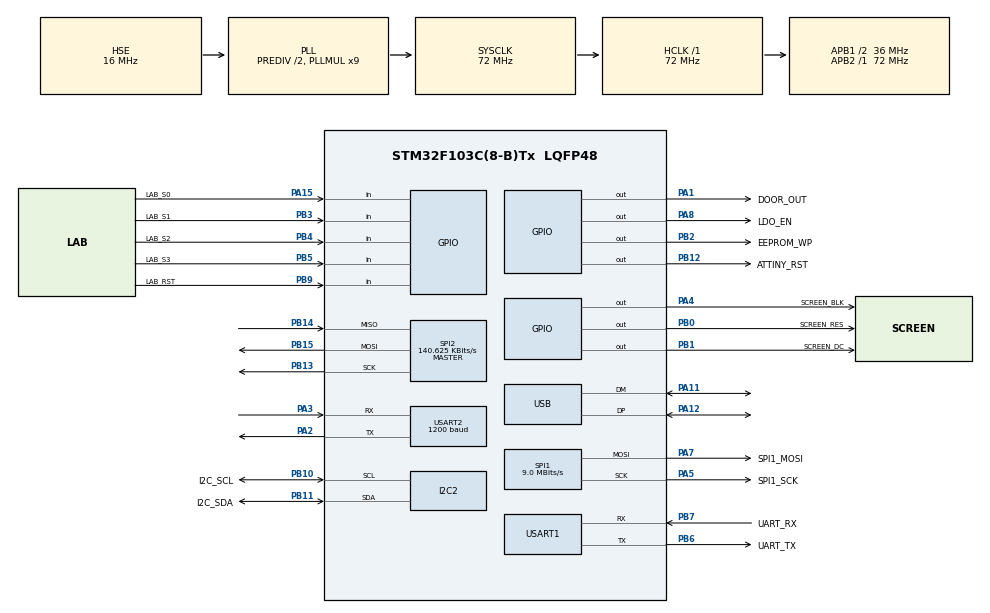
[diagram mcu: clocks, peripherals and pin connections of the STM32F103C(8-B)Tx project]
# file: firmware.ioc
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Mcu.Family=STM32F1
Mcu.Name=STM32F103C(8-B)Tx
Mcu.Package=LQFP48
NVIC.PriorityGroup=NVIC_PRIORITYGROUP_4
PA1.GPIO_Label=DOOR_OUT
PA1.Signal=GPIO_Output
PA11.Mode=Device
PA11.Signal=USB_DM
PA12.Mode=Device
PA12.Signal=USB_DP
PA13.GPIO_Label=SWDIO
PA13.Mode=Serial_Wire
PA13.Signal=SYS_JTMS-SWDIO
PA14.GPIO_Label=SWDCLK
PA14.Mode=Serial_Wire
PA14.Signal=SYS_JTCK-SWCLK
PA15.GPIO_Label=LAB_S0
PA15.Signal=GPIO_Input
PA2.Mode=Asynchronous
PA2.Signal=USART2_TX
PA3.Mode=Asynchronous
PA3.Signal=USART2_RX
PA4.GPIO_Label=SCREEN_BLK
PA4.Signal=GPIO_Output
PA5.GPIO_Label=SPI1_SCK
PA5.Mode=TX_Only_Simplex_Unidirect_Master
PA5.Signal=SPI1_SCK
PA7.GPIO_Label=SPI1_MOSI
PA7.Mode=TX_Only_Simplex_Unidirect_Master
PA7.Signal=SPI1_MOSI
PA8.GPIO_Label=LDO_EN
PA8.Signal=GPIO_Output
PB0.GPIO_Label=SCREEN_RES
PB0.Signal=GPIO_Output
PB1.GPIO_Label=SCREEN_DC
PB1.Signal=GPIO_Output
PB10.GPIO_Label=I2C_SCL
PB10.Mode=I2C
PB10.Signal=I2C2_SCL
PB11.GPIO_Label=I2C_SDA
PB11.Mode=I2C
PB11.Signal=I2C2_SDA
PB12.GPIO_Label=ATTINY_RST
PB12.Signal=GPIO_Output
PB13.Mode=Full_Duplex_Master
PB13.Signal=SPI2_SCK
PB14.Mode=Full_Duplex_Master
PB14.Signal=SPI2_MISO
PB15.Mode=Full_Duplex_Master
PB15.Signal=SPI2_MOSI
PB2.GPIO_Label=EEPROM_WP
PB2.GPIO_ModeDefaultOutputPP=GPIO_MODE_OUTPUT_OD
PB2.GPIO_PuPd=GPIO_NOPULL
PB2.Signal=GPIO_Output
PB3.GPIO_Label=LAB_S1
PB3.Signal=GPIO_Input
PB4.GPIO_Label=LAB_S2
PB4.Signal=GPIO_Input
PB5.GPIO_Label=LAB_S3
PB5.Signal=GPIO_Input
PB6.GPIO_Label=UART_TX
PB6.Mode=Asynchronous
PB6.Signal=USART1_TX
PB7.GPIO_Label=UART_RX
PB7.Mode=Asynchronous
PB7.Signal=USART1_RX
PB9.GPIO_Label=LAB_RST
PB9.Signal=GPIO_Input
PD0-OSC_IN.GPIO_Label=HSE_IN
PD0-OSC_IN.Mode=HSE-External-Oscillator
PD0-OSC_IN.Signal=RCC_OSC_IN
PD1-OSC_OUT.GPIO_Label=HSE_OUT
PD1-OSC_OUT.Mode=HSE-External-Oscillator
PD1-OSC_OUT.Signal=RCC_OSC_OUT
ProjectManager.HeapSize=0x200
ProjectManager.StackSize=0x400
ProjectManager.TargetToolchain=CMake
RCC.AHBFreq_Value=72000000
RCC.APB1CLKDivider=RCC_HCLK_DIV2
RCC.APB1Freq_Value=36000000
RCC.APB1TimFreq_Value=72000000
RCC.APB2Freq_Value=72000000
RCC.APB2TimFreq_Value=72000000
RCC.HCLKFreq_Value=72000000
RCC.HSEDivPLL=RCC_HSE_PREDIV_DIV2
RCC.HSE_VALUE=16000000
RCC.PLLMUL=RCC_PLL_MUL9
RCC.SYSCLKFreq_VALUE=72000000
RCC.SYSCLKSource=RCC_SYSCLKSOURCE_PLLCLK
RCC.USBFreq_Value=48000000
RCC.USBPrescaler=RCC_USBCLKSOURCE_PLL_DIV1_5
SPI1.BaudRatePrescaler=SPI_BAUDRATEPRESCALER_8
SPI1.CLKPhase=SPI_PHASE_2EDGE
SPI1.CLKPolarity=SPI_POLARITY_HIGH
SPI1.CalculateBaudRate=9.0 MBits/s
SPI1.Direction=SPI_DIRECTION_2LINES
SPI1.Mode=SPI_MODE_MASTER
SPI1.VirtualType=VM_MASTER
SPI2.BaudRatePrescaler=SPI_BAUDRATEPRESCALER_256
SPI2.CalculateBaudRate=140.625 KBits/s
SPI2.Direction=SPI_DIRECTION_2LINES
SPI2.Mode=SPI_MODE_MASTER
SPI2.VirtualType=VM_MASTER
USART1.VirtualMode=VM_ASYNC
USART2.BaudRate=1200
USART2.Mode=MODE_RX
USART2.VirtualMode=VM_ASYNC
board=custom

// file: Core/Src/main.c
/* USER CODE BEGIN Header */
/**
  ******************************************************************************
  * @file           : main.c
  * @brief          : Main program body
  ******************************************************************************
  * @attention
  *
  * Copyright (c) 2025 STMicroelectronics.
  * All rights reserved.
  *
  * This software is licensed under terms that can be found in the LICENSE file
  * in the root directory of this software component.
  * If no LICENSE file comes with this software, it is provided AS-IS.
  *
  ******************************************************************************
  */
/* USER CODE END Header */
#include "main.h"

/* USER CODE BEGIN Includes */
#include "lab_bootstrap.h"
/* USER CODE END Includes */

I2C_HandleTypeDef hi2c2;

SPI_HandleTypeDef hspi1;
SPI_HandleTypeDef hspi2;

UART_HandleTypeDef huart1;
UART_HandleTypeDef huart2;

PCD_HandleTypeDef hpcd_USB_FS;

void SystemClock_Config(void);
static void MX_GPIO_Init(void);
static void MX_I2C2_Init(void);
static void MX_SPI1_Init(void);
static void MX_USART1_UART_Init(void);
static void MX_USB_PCD_Init(void);
static void MX_SPI2_Init(void);
static void MX_USART2_UART_Init(void);

int main(void)
{

  /* MCU Configuration--------------------------------------------------------*/

  /* Reset of all peripherals, Initializes the Flash interface and the Systick. */
  HAL_Init();

  /* USER CODE BEGIN Init */
  #ifndef SIMULATION // Hacky solution to keep the conditional definition inside user code to keep it across CubeMX code re-generations
  /* USER CODE END Init */

  /* Configure the system clock */
  SystemClock_Config();

  /* USER CODE BEGIN SysInit */
  #endif
  /* USER CODE END SysInit */

  /* Initialize all configured peripherals */
  MX_GPIO_Init();
  MX_I2C2_Init();
  MX_SPI1_Init();
  MX_USART1_UART_Init();
  MX_USB_PCD_Init();
  MX_SPI2_Init();
  MX_USART2_UART_Init();
  /* USER CODE BEGIN 2 */
  LabBootstrap_Start();
  /* USER CODE END 2 */

  /* Infinite loop */
  while (1)
  {

  }
}

void SystemClock_Config(void)
{
  RCC_OscInitTypeDef RCC_OscInitStruct = {0};
  RCC_ClkInitTypeDef RCC_ClkInitStruct = {0};
  RCC_PeriphCLKInitTypeDef PeriphClkInit = {0};

  /** Initializes the RCC Oscillators according to the specified parameters
  * in the RCC_OscInitTypeDef structure.
  */
  RCC_OscInitStruct.OscillatorType = RCC_OSCILLATORTYPE_HSE;
  RCC_OscInitStruct.HSEState = RCC_HSE_ON;
  RCC_OscInitStruct.HSEPredivValue = RCC_HSE_PREDIV_DIV2;
  RCC_OscInitStruct.HSIState = RCC_HSI_ON;
  RCC_OscInitStruct.PLL.PLLState = RCC_PLL_ON;
  RCC_OscInitStruct.PLL.PLLSource = RCC_PLLSOURCE_HSE;
  RCC_OscInitStruct.PLL.PLLMUL = RCC_PLL_MUL9;
  if (HAL_RCC_OscConfig(&RCC_OscInitStruct) != HAL_OK)
  {
    Error_Handler();
  }

  /** Initializes the CPU, AHB and APB buses clocks
  */
  RCC_ClkInitStruct.ClockType = RCC_CLOCKTYPE_HCLK|RCC_CLOCKTYPE_SYSCLK
                              |RCC_CLOCKTYPE_PCLK1|RCC_CLOCKTYPE_PCLK2;
  RCC_ClkInitStruct.SYSCLKSource = RCC_SYSCLKSOURCE_PLLCLK;
  RCC_ClkInitStruct.AHBCLKDivider = RCC_SYSCLK_DIV1;
  RCC_ClkInitStruct.APB1CLKDivider = RCC_HCLK_DIV2;
  RCC_ClkInitStruct.APB2CLKDivider = RCC_HCLK_DIV1;

  if (HAL_RCC_ClockConfig(&RCC_ClkInitStruct, FLASH_LATENCY_2) != HAL_OK)
  {
    Error_Handler();
  }
  PeriphClkInit.PeriphClockSelection = RCC_PERIPHCLK_USB;
  PeriphClkInit.UsbClockSelection = RCC_USBCLKSOURCE_PLL_DIV1_5;
  if (HAL_RCCEx_PeriphCLKConfig(&PeriphClkInit) != HAL_OK)
  {
    Error_Handler();
  }
}

static void MX_I2C2_Init(void)
{

  hi2c2.Instance = I2C2;
  hi2c2.Init.ClockSpeed = 100000;
  hi2c2.Init.DutyCycle = I2C_DUTYCYCLE_2;
  hi2c2.Init.OwnAddress1 = 0;
  hi2c2.Init.AddressingMode = I2C_ADDRESSINGMODE_7BIT;
  hi2c2.Init.DualAddressMode = I2C_DUALADDRESS_DISABLE;
  hi2c2.Init.OwnAddress2 = 0;
  hi2c2.Init.GeneralCallMode = I2C_GENERALCALL_DISABLE;
  hi2c2.Init.NoStretchMode = I2C_NOSTRETCH_DISABLE;
  if (HAL_I2C_Init(&hi2c2) != HAL_OK)
  {
    Error_Handler();
  }

}

static void MX_SPI1_Init(void)
{

  /* SPI1 parameter configuration*/
  hspi1.Instance = SPI1;
  hspi1.Init.Mode = SPI_MODE_MASTER;
  hspi1.Init.Direction = SPI_DIRECTION_2LINES;
  hspi1.Init.DataSize = SPI_DATASIZE_8BIT;
  hspi1.Init.CLKPolarity = SPI_POLARITY_HIGH;
  hspi1.Init.CLKPhase = SPI_PHASE_2EDGE;
  hspi1.Init.NSS = SPI_NSS_SOFT;
  hspi1.Init.BaudRatePrescaler = SPI_BAUDRATEPRESCALER_8;
  hspi1.Init.FirstBit = SPI_FIRSTBIT_MSB;
  hspi1.Init.TIMode = SPI_TIMODE_DISABLE;
  hspi1.Init.CRCCalculation = SPI_CRCCALCULATION_DISABLE;
  hspi1.Init.CRCPolynomial = 10;
  if (HAL_SPI_Init(&hspi1) != HAL_OK)
  {
    Error_Handler();
  }

}

static void MX_SPI2_Init(void)
{

  /* SPI2 parameter configuration*/
  hspi2.Instance = SPI2;
  hspi2.Init.Mode = SPI_MODE_MASTER;
  hspi2.Init.Direction = SPI_DIRECTION_2LINES;
  hspi2.Init.DataSize = SPI_DATASIZE_8BIT;
  hspi2.Init.CLKPolarity = SPI_POLARITY_LOW;
  hspi2.Init.CLKPhase = SPI_PHASE_1EDGE;
  hspi2.Init.NSS = SPI_NSS_SOFT;
  hspi2.Init.BaudRatePrescaler = SPI_BAUDRATEPRESCALER_256;
  hspi2.Init.FirstBit = SPI_FIRSTBIT_MSB;
  hspi2.Init.TIMode = SPI_TIMODE_DISABLE;
  hspi2.Init.CRCCalculation = SPI_CRCCALCULATION_DISABLE;
  hspi2.Init.CRCPolynomial = 10;
  if (HAL_SPI_Init(&hspi2) != HAL_OK)
  {
    Error_Handler();
  }

}

static void MX_USART1_UART_Init(void)
{

  huart1.Instance = USART1;
  huart1.Init.BaudRate = 115200;
  huart1.Init.WordLength = UART_WORDLENGTH_8B;
  huart1.Init.StopBits = UART_STOPBITS_1;
  huart1.Init.Parity = UART_PARITY_NONE;
  huart1.Init.Mode = UART_MODE_TX_RX;
  huart1.Init.HwFlowCtl = UART_HWCONTROL_NONE;
  huart1.Init.OverSampling = UART_OVERSAMPLING_16;
  if (HAL_UART_Init(&huart1) != HAL_OK)
  {
    Error_Handler();
  }

}

static void MX_USART2_UART_Init(void)
{

  huart2.Instance = USART2;
  huart2.Init.BaudRate = 1200;
  huart2.Init.WordLength = UART_WORDLENGTH_8B;
  huart2.Init.StopBits = UART_STOPBITS_1;
  huart2.Init.Parity = UART_PARITY_NONE;
  huart2.Init.Mode = UART_MODE_RX;
  huart2.Init.HwFlowCtl = UART_HWCONTROL_NONE;
  huart2.Init.OverSampling = UART_OVERSAMPLING_16;
  if (HAL_UART_Init(&huart2) != HAL_OK)
  {
    Error_Handler();
  }

}

static void MX_USB_PCD_Init(void)
{

  hpcd_USB_FS.Instance = USB;
  hpcd_USB_FS.Init.dev_endpoints = 8;
  hpcd_USB_FS.Init.speed = PCD_SPEED_FULL;
  hpcd_USB_FS.Init.low_power_enable = DISABLE;
  hpcd_USB_FS.Init.lpm_enable = DISABLE;
  hpcd_USB_FS.Init.battery_charging_enable = DISABLE;
  if (HAL_PCD_Init(&hpcd_USB_FS) != HAL_OK)
  {
    Error_Handler();
  }

}

static void MX_GPIO_Init(void)
{
  GPIO_InitTypeDef GPIO_InitStruct = {0};

  /* GPIO Ports Clock Enable */
  __HAL_RCC_GPIOD_CLK_ENABLE();
  __HAL_RCC_GPIOA_CLK_ENABLE();
  __HAL_RCC_GPIOB_CLK_ENABLE();

  /*Configure GPIO pin Output Level */
  HAL_GPIO_WritePin(GPIOA, DOOR_OUT_Pin|SCREEN_BLK_Pin|LDO_EN_Pin, GPIO_PIN_RESET);

  /*Configure GPIO pin Output Level */
  HAL_GPIO_WritePin(GPIOB, SCREEN_RES_Pin|SCREEN_DC_Pin|EEPROM_WP_Pin|ATTINY_RST_Pin, GPIO_PIN_RESET);

  /*Configure GPIO pins : DOOR_OUT_Pin SCREEN_BLK_Pin LDO_EN_Pin */
  GPIO_InitStruct.Pin = DOOR_OUT_Pin|SCREEN_BLK_Pin|LDO_EN_Pin;
  GPIO_InitStruct.Mode = GPIO_MODE_OUTPUT_PP;
  GPIO_InitStruct.Pull = GPIO_NOPULL;
  GPIO_InitStruct.Speed = GPIO_SPEED_FREQ_LOW;
  HAL_GPIO_Init(GPIOA, &GPIO_InitStruct);

  /*Configure GPIO pins : SCREEN_RES_Pin SCREEN_DC_Pin ATTINY_RST_Pin */
  GPIO_InitStruct.Pin = SCREEN_RES_Pin|SCREEN_DC_Pin|ATTINY_RST_Pin;
  GPIO_InitStruct.Mode = GPIO_MODE_OUTPUT_PP;
  GPIO_InitStruct.Pull = GPIO_NOPULL;
  GPIO_InitStruct.Speed = GPIO_SPEED_FREQ_LOW;
  HAL_GPIO_Init(GPIOB, &GPIO_InitStruct);

  /*Configure GPIO pin : EEPROM_WP_Pin */
  GPIO_InitStruct.Pin = EEPROM_WP_Pin;
  GPIO_InitStruct.Mode = GPIO_MODE_OUTPUT_OD;
  GPIO_InitStruct.Pull = GPIO_NOPULL;
  GPIO_InitStruct.Speed = GPIO_SPEED_FREQ_LOW;
  HAL_GPIO_Init(EEPROM_WP_GPIO_Port, &GPIO_InitStruct);

  /*Configure GPIO pin : LAB_S0_Pin */
  GPIO_InitStruct.Pin = LAB_S0_Pin;
  GPIO_InitStruct.Mode = GPIO_MODE_INPUT;
  GPIO_InitStruct.Pull = GPIO_NOPULL;
  HAL_GPIO_Init(LAB_S0_GPIO_Port, &GPIO_InitStruct);

  /*Configure GPIO pins : LAB_S1_Pin LAB_S2_Pin LAB_S3_Pin LAB_RST_Pin */
  GPIO_InitStruct.Pin = LAB_S1_Pin|LAB_S2_Pin|LAB_S3_Pin|LAB_RST_Pin;
  GPIO_InitStruct.Mode = GPIO_MODE_INPUT;
  GPIO_InitStruct.Pull = GPIO_NOPULL;
  HAL_GPIO_Init(GPIOB, &GPIO_InitStruct);

}

void Error_Handler(void)
{
  __disable_irq();
  while (1)
  {
  }
}
